# AT32F423 register map
Vendor: Keil; Series: AT32F423; File version: 1.0
CPU: CM4 r0p1, little endian, no MPU, FPU, 4 interrupt priority bits
Registers are 32-bit, read-write, reset 0x0 unless marked. A register's access mark holds for its fields unless they carry their own. Offsets are from the block's base; [hi:lo] are bit positions.

## USART1 — Universal synchronous asynchronous receiver transmitter
Base 0x40011000
Same registers: USART2 0x40004400, USART3 0x40004800, USART4 0x40004C00, USART5 0x40005000, USART7 0x40007800, USART8 0x40007C00, USART6 0x40011400
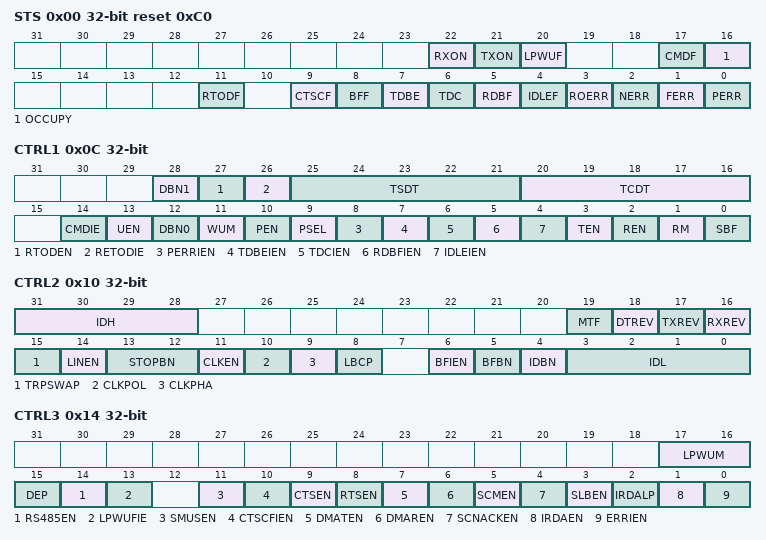
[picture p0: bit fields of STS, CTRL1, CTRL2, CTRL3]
0x00 STS reset 0xC0 — Status register
  [22] RXON ro — Receiver enabled flag
  [21] TXON ro — Transmitter enabled flag
  [20] LPWUF ro — Low power wakeup flag
  [17] CMDF ro — Character match detect flag
  [16] OCCUPY ro — Receiver occupied flag
  [11] RTODF ro — Receiver time out detection flag
  [9] CTSCF write-0-clears — CTS change flag
    on read: 0=No change on the CTS status line; 1=Change (A change occurs on the CTS status line) | on write: 0=Clear CTS change flag
  [8] BFF write-0-clears — Break frame flag
    on read: 0=NoBreak (Break frame is not detected); 1=Break frame is detected | on write: 0=Clear break frame flag
  [7] TDBE ro — Transmit data buffer empty
    0=NotEmpty (Data is not transferred to the shift register); 1=Empty (Data is transferred to the shift register)
  [6] TDC write-0-clears — Transmit data complete
    on read: 0=NotCompleted (Transmission is not completed); 1=Completed (Transmission is completed) | on write: 0=Clear transmit data complete flag
  [5] RDBF write-0-clears — Receive data buffer full
    on read: 0=NotFull (Data is not received); 1=Full (Data is received) | on write: 0=Clear receive buffer full flag
  [4] IDLEF ro — IDLE flag
    0=No idle line is detected; 1=Idle line is detected
  [3] ROERR ro — Receiver overflow error
    0=NoError (No overflow error); 1=Overflow error is detected
  [2] NERR ro — Noise error
    0=No noise is detected; 1=Noise is detected
  [1] FERR ro — Framing error
    0=NoError (No framing error is detected); 1=Error (Framing error is detected)
  [0] PERR ro — Parity error
    0=NoError (No parity error occurs); 1=Error (Parity error occurs)
0x04 DT — Data register
  [8:0] DT — Data value
0x08 BAUDR — Baud rate register
  [15:0] DIV — Division
0x0C CTRL1 — Control register 1
  [28] DBN1 — DBN[1] — high bit of data bit number. Combined with DBN0 to form DBN[1:0]. 10: 7 data bits, 00: 8 data bits, 01: 9 data bits, 11: Forbidden. When parity is enabled, the valid data bit count is reduced by one and the MSB is replaced with the parity bit
  [27] RTODEN — Receiver time out detection enable
  [26] RETODIE — Receiver time out detection interrupt enable
  [25:21] TSDT — transmit start delay time
  [20:16] TCDT — transmit complete delay time
  [14] CMDIE — Character match detection interrupt enable
  [13] UEN — USART enable
    on read: 0=Disabled (USART is disabled); 1=Enabled (USART is enabled) | on write: 0=Disable (USART disable); 1=Enable (USART enable)
  [12] DBN0 — DBN[0] — low bit of data bit number. Combined with DBN1 to form DBN[1:0]. 10: 7 data bits, 00: 8 data bits, 01: 9 data bits, 11: Forbidden. When parity is enabled, the valid data bit count is reduced by one and the MSB is replaced with the parity bit
  [11] WUM — Wake up mode
    0=Idle (Waken up by idle line); 1=ID (Waken up by ID match)
  [10] PEN — Parity enable
    on read: 0=Disabled (Parity is disabled); 1=Enabled (Parity is enabled) | on write: 0=Disable (Parity disable); 1=Enable (Parity enable)
  [9] PSEL — Parity selection
    0=Even parity; 1=Odd (Odd parity)
  [8] PERRIEN — PERR interrupt enable
    on read: 0=Disabled (PERR interrupt is disabled); 1=Enabled (PERR interrupt is enabled) | on write: 0=Disable (PERR interrupt disable); 1=Enable (PERR interrupt enable)
  [7] TDBEIEN — TDBE interrupt enable
    on read: 0=Disabled (TDBE interrupt is disabled); 1=Enabled (TDBE interrupt is enabled) | on write: 0=Disable (TDBE interrupt disable); 1=Enable (TDBE interrupt enable)
  [6] TDCIEN — TDC interrupt enable
    on read: 0=Disabled (TDC interrupt is disabled); 1=Enabled (TDC interrupt is enabled) | on write: 0=Disable (TDC interrupt disable); 1=Enable (TDC interrupt enable)
  [5] RDBFIEN — RDBF interrupt enable
    on read: 0=Disabled (RDBF interrupt is disabled); 1=Enabled (RDBF interrupt is enabled) | on write: 0=Disable (RDBF interrupt disable); 1=Enable (RDBF interrupt enable)
  [4] IDLEIEN — IDLE interrupt enable
    on read: 0=Disabled (IDLE interrupt is disabled); 1=Enabled (IDLE interrupt is enabled) | on write: 0=Disable (IDLE interrupt disable); 1=Enable (IDLE interrupt enable)
  [3] TEN — Transmitter enable
    on read: 0=Disabled (Transmitter is disabled); 1=Enabled (Transmitter is enabled) | on write: 0=Disable (Transmitter disable); 1=Enable (Transmitter enable)
  [2] REN — Receiver enable
    on read: 0=Disabled (Receiver is disabled); 1=Enabled (Receiver is enabled) | on write: 0=Disable (Receiver disable); 1=Enable (Receiver enable)
  [1] RM — Receiver mute
    0=Active (Receiver is in active mode); 1=Mute (Receiver is in mute mode)
  [0] SBF — Send break frame
    on read: 0=NoTransmission (No break frame is transmitted); 1=Transmitting (Break frame is transmitted) | on write: 0=Clear send break frame; 1=Send break frame
0x10 CTRL2 — Control register 2
  [31:28] IDH — bit 7-4 for usart identification
  [19] MTF — MSB transmit first
  [18] DTREV — DT register polarity reverse
  [17] TXREV — TX polarity reverse
  [16] RXREV — RX polarity reverse
  [15] TRPSWAP — Transmit receive pin swap
    0=Normal (No swap); 1=Swapped (TX and RX pins are swapped)
  [14] LINEN — LIN mode enable
    on read: 0=Disabled (LIN mode is disabled); 1=Enabled (LIN mode is enabled) | on write: 0=Disable (LIN mode disable); 1=Enable (LIN mode enable)
  [13:12] STOPBN — STOP bit num
    0=bit1 (1 stop bit); 1=bit05 (0.5 stop bit); 2=bit2 (2 stop bits); 3=bit15 (1.5 stop bit)
  [11] CLKEN — Clock enable
    on read: 0=Disabled (Clock is disabled); 1=Enabled (Clock is enabled) | on write: 0=Disable (Clock disable); 1=Enable (Clock enable)
  [10] CLKPOL — Clock polarity
    0=Low (Clock output low); 1=High (Clock output high)
  [9] CLKPHA — Clock phase
    0=First (Data capture is done on the first clock edge); 1=Second (Data capture is done on the second clock edge)
  [8] LBCP — Last bit clock pulse
    on read: 0=Disabled (The clock pulse of the last data bit is no output on the clock pin); 1=Enabled (The clock pulse of the last data bit is output on the clock pin) | on write: 0=Disable (The clock pulse of the last data bit is no output on the clock pin); 1=Enable (The clock pulse of the last data bit is output on the clock pin)
  [6] BFIEN — Break frame interrupt enable
    on read: 0=Disabled (Break frame interrupt is disabled); 1=Enabled (Break frame interrupt is enabled) | on write: 0=Disable (Break frame interrupt disable); 1=Enable (Break frame interrupt enable)
  [5] BFBN — Break frame bit num
    0=bit10 (10-bit break frame); 1=bit11 (11-bit break frame)
  [4] IDBN — Identification bit num
    0=Bit4 (4-bit ID); 1=Databits_minus_1 (data_bits - 1 ID)
  [3:0] IDL — bit 3-0 for usart identification
0x14 CTRL3 — Control register 3
  [17:16] LPWUM — Low power wakeup method
  [15] DEP — DE polarity selection
    0=High (DE signal is active high); 1=Low (DE signal is active low)
  [14] RS485EN — RS485 enable
    on read: 0=Disabled (RS-485 mode is disabled); 1=Enabled (RS-485 mode is enabled. The control signal DE outputs on the RTS pin.) | on write: 0=Disable (RS-485 mode disable); 1=Enable (RS-485 mode enable. The control signal DE outputs on the RTS pin.)
  [13] LPWUFIE — Low power wakeup flag interrupt enable
  [11] SMUSEN — Deepsleep mode usart enable
  [10] CTSCFIEN — CTSCF interrupt enable
    on read: 0=Disabled (CTSCF interrupt is disabled); 1=Enabled (CTSCF interrupt is enabled) | on write: 0=Disable (CTSCF interrupt disable); 1=Enable (CTSCF interrupt enable)
  [9] CTSEN — CTS enable
    on read: 0=Disabled (CTS is disabled); 1=Enabled (CTS is enabled) | on write: 0=Disable (CTS disable); 1=Enable (CTS enable)
  [8] RTSEN — RTS enable
    on read: 0=Disabled (RTS is disabled); 1=Enabled (RTS is enabled) | on write: 0=Disable (RTS disable); 1=Enable (RTS enable)
  [7] DMATEN — DMA transmitter enable
    on read: 0=Disabled (DMA transmitter is disabled); 1=Enabled (DMA transmitter is enabled) | on write: 0=Disable (DMA transmitter disable); 1=Enable (DMA transmitter enable)
  [6] DMAREN — DMA receiver enable
    on read: 0=Disabled (DMA receiver is disabled); 1=Enabled (DMA receiver is enabled) | on write: 0=Disable (DMA receiver disable); 1=Enable (DMA receiver enable)
  [5] SCMEN — Smartcard mode enable
    on read: 0=Disabled (Smartcard mode is disabled); 1=Enabled (Smartcard mode is enabled) | on write: 0=Disable (Smartcard mode disable); 1=Enable (Smartcard mode enable)
  [4] SCNACKEN — Smartcard NACK enable
    on read: 0=Disabled (Smartcard NACK is disabled); 1=Enabled (Smartcard NACK is enabled) | on write: 0=Disable (Smartcard NACK disable); 1=Enable (Smartcard NACK enable)
  [3] SLBEN — Single line bidirectional half-duplex enable
    on read: 0=Disabled (Single-wire bidirectional half-duplex is disabled); 1=Enabled (Single-wire bidirectional half-duplex is enabled) | on write: 0=Disable (Single-wire bidirectional half-duplex disable); 1=Enable (Single-wire bidirectional half-duplex enable)
  [2] IRDALP — IrDA low-power mode
    on read: 0=Disabled (IrDA low-power mode is disabled); 1=Enabled (IrDA low-power mode is enabled) | on write: 0=Disable (IrDA low-power mode disable); 1=Enable (IrDA low-power mode enable)
  [1] IRDAEN — IrDA enable
    on read: 0=Disabled (IrDA is disabled); 1=Enabled (IrDA is enabled) | on write: 0=Disable (IrDA disable); 1=Enable (IrDA enable)
  [0] ERRIEN — Error interrupt enable
    on read: 0=Disabled (Error interrupt is disabled); 1=Enabled (Error interrupt is enabled) | on write: 0=Disable (Error interrupt disable); 1=Enable (Error interrupt enable)
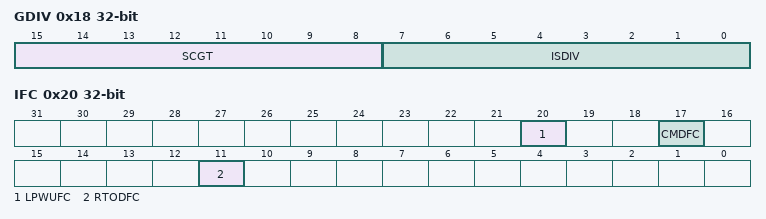
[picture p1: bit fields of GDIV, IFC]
0x18 GDIV — Guard time and division register
  [15:8] SCGT — Smart card guard time value
  [7:0] ISDIV range 1..255 — IrDA/smartcard division value
0x1C RTOV — Receiver time out value register
  [23:0] RTOV — Receiver time out value
0x20 IFC wo — Interrupt flag clear register
  [20] LPWUFC — Low power wake up flag clear
  [17] CMDFC — Character match flag clear
  [11] RTODFC — Receiver time out detection flag clear
